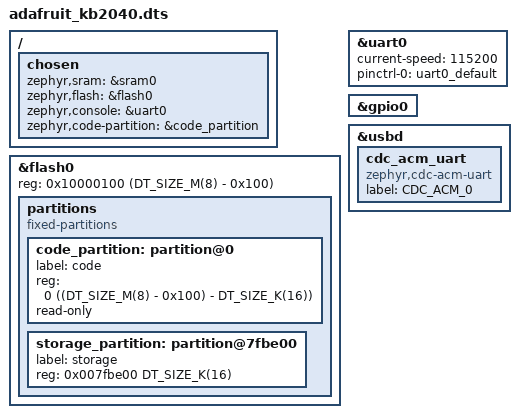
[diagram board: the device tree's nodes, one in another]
/*
 * Copyright (c) 2021 Yonatan Schachter
 *
 * SPDX-License-Identifier: Apache-2.0
 */

/dts-v1/;

#include <raspberrypi/rp2040.dtsi>
#include "adafruit_kb2040-pinctrl.dtsi"
#include "sparkfun_pro_micro.dtsi"

/ {
	chosen {
		zephyr,sram = &sram0;
		zephyr,flash = &flash0;
		zephyr,console = &uart0;
		zephyr,code-partition = &code_partition;
	};
};

&flash0 {
	/* 8MB of flash minus the 0x100 used for
	 * the second stage bootloader
	 */
	reg = <0x10000100 (DT_SIZE_M(8) - 0x100)>;

	partitions {
		compatible = "fixed-partitions";
		#address-cells = <1>;
		#size-cells = <1>;

		/*
		 * Start at the beginning of usable flash, 8MB minus the
		 * second stage space and the 16 KiB reserved for settings
		 */
		code_partition: partition@0 {
			label = "code";
			reg = <0 ((DT_SIZE_M(8) - 0x100) - DT_SIZE_K(16))>;
			read-only;
		};

		/*
		 * The final 16 KiB is reserved for the application.
		 * Storage partition may be used by FCB or LittleFS.
		 */
		storage_partition: partition@7fbe00 {
			label = "storage";
			reg = <0x007fbe00 DT_SIZE_K(16)>;
		};
	};
};

&uart0 {
	current-speed = <115200>;
	status = "okay";
	pinctrl-0 = <&uart0_default>;
	pinctrl-names = "default";
};

&gpio0 {
	status = "okay";
};

&usbd {
	status = "okay";
	cdc_acm_uart: cdc_acm_uart {
		compatible = "zephyr,cdc-acm-uart";
		label = "CDC_ACM_0";  
        };
};
